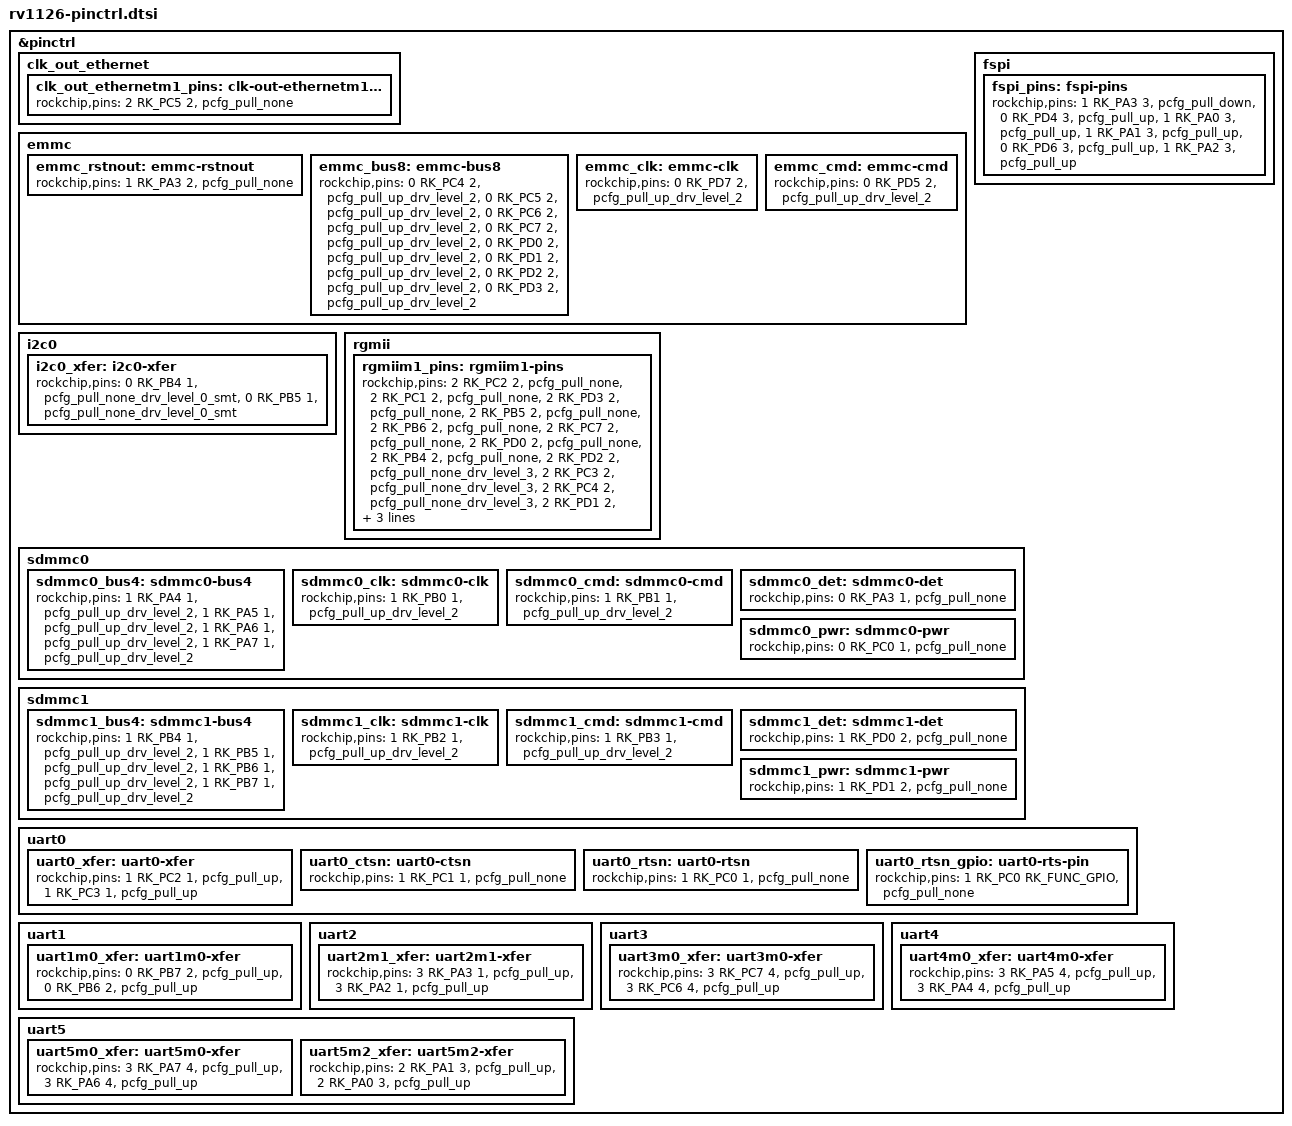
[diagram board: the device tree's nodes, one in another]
#include <dt-bindings/pinctrl/rockchip.h>
#include <arm64/rockchip/rockchip-pinconf.dtsi>
&pinctrl {
	clk_out_ethernet {
		/omit-if-no-ref/
		clk_out_ethernetm1_pins: clk-out-ethernetm1-pins {
			rockchip,pins =
				<2 RK_PC5 2 &pcfg_pull_none>;
		};
	};
	emmc {
		/omit-if-no-ref/
		emmc_rstnout: emmc-rstnout {
			rockchip,pins =
				<1 RK_PA3 2 &pcfg_pull_none>;
		};
		/omit-if-no-ref/
		emmc_bus8: emmc-bus8 {
			rockchip,pins =
				<0 RK_PC4 2 &pcfg_pull_up_drv_level_2>,
				<0 RK_PC5 2 &pcfg_pull_up_drv_level_2>,
				<0 RK_PC6 2 &pcfg_pull_up_drv_level_2>,
				<0 RK_PC7 2 &pcfg_pull_up_drv_level_2>,
				<0 RK_PD0 2 &pcfg_pull_up_drv_level_2>,
				<0 RK_PD1 2 &pcfg_pull_up_drv_level_2>,
				<0 RK_PD2 2 &pcfg_pull_up_drv_level_2>,
				<0 RK_PD3 2 &pcfg_pull_up_drv_level_2>;
		};
		/omit-if-no-ref/
		emmc_clk: emmc-clk {
			rockchip,pins =
				<0 RK_PD7 2 &pcfg_pull_up_drv_level_2>;
		};
		/omit-if-no-ref/
		emmc_cmd: emmc-cmd {
			rockchip,pins =
				<0 RK_PD5 2 &pcfg_pull_up_drv_level_2>;
		};
	};
	fspi {
		/omit-if-no-ref/
		fspi_pins: fspi-pins {
			rockchip,pins =
				<1 RK_PA3 3 &pcfg_pull_down>,
				<0 RK_PD4 3 &pcfg_pull_up>,
				<1 RK_PA0 3 &pcfg_pull_up>,
				<1 RK_PA1 3 &pcfg_pull_up>,
				<0 RK_PD6 3 &pcfg_pull_up>,
				<1 RK_PA2 3 &pcfg_pull_up>;
		};
	};
	i2c0 {
		/omit-if-no-ref/
		i2c0_xfer: i2c0-xfer {
			rockchip,pins =
				<0 RK_PB4 1 &pcfg_pull_none_drv_level_0_smt>,
				<0 RK_PB5 1 &pcfg_pull_none_drv_level_0_smt>;
		};
	};
	rgmii {
		/omit-if-no-ref/
		rgmiim1_pins: rgmiim1-pins {
			rockchip,pins =
				<2 RK_PC2 2 &pcfg_pull_none>,
				<2 RK_PC1 2 &pcfg_pull_none>,
				<2 RK_PD3 2 &pcfg_pull_none>,
				<2 RK_PB5 2 &pcfg_pull_none>,
				<2 RK_PB6 2 &pcfg_pull_none>,
				<2 RK_PC7 2 &pcfg_pull_none>,
				<2 RK_PD0 2 &pcfg_pull_none>,
				<2 RK_PB4 2 &pcfg_pull_none>,
				<2 RK_PD2 2 &pcfg_pull_none_drv_level_3>,
				<2 RK_PC3 2 &pcfg_pull_none_drv_level_3>,
				<2 RK_PC4 2 &pcfg_pull_none_drv_level_3>,
				<2 RK_PD1 2 &pcfg_pull_none_drv_level_3>,
				<2 RK_PA4 2 &pcfg_pull_none_drv_level_3>,
				<2 RK_PC6 2 &pcfg_pull_none_drv_level_3>;
		};
	};
	sdmmc0 {
		/omit-if-no-ref/
		sdmmc0_bus4: sdmmc0-bus4 {
			rockchip,pins =
				<1 RK_PA4 1 &pcfg_pull_up_drv_level_2>,
				<1 RK_PA5 1 &pcfg_pull_up_drv_level_2>,
				<1 RK_PA6 1 &pcfg_pull_up_drv_level_2>,
				<1 RK_PA7 1 &pcfg_pull_up_drv_level_2>;
		};
		/omit-if-no-ref/
		sdmmc0_clk: sdmmc0-clk {
			rockchip,pins =
				<1 RK_PB0 1 &pcfg_pull_up_drv_level_2>;
		};
		/omit-if-no-ref/
		sdmmc0_cmd: sdmmc0-cmd {
			rockchip,pins =
				<1 RK_PB1 1 &pcfg_pull_up_drv_level_2>;
		};
		/omit-if-no-ref/
		sdmmc0_det: sdmmc0-det {
			rockchip,pins =
				<0 RK_PA3 1 &pcfg_pull_none>;
		};
		/omit-if-no-ref/
		sdmmc0_pwr: sdmmc0-pwr {
			rockchip,pins =
				<0 RK_PC0 1 &pcfg_pull_none>;
		};
	};
	sdmmc1 {
		/omit-if-no-ref/
		sdmmc1_bus4: sdmmc1-bus4 {
			rockchip,pins =
				<1 RK_PB4 1 &pcfg_pull_up_drv_level_2>,
				<1 RK_PB5 1 &pcfg_pull_up_drv_level_2>,
				<1 RK_PB6 1 &pcfg_pull_up_drv_level_2>,
				<1 RK_PB7 1 &pcfg_pull_up_drv_level_2>;
		};
		/omit-if-no-ref/
		sdmmc1_clk: sdmmc1-clk {
			rockchip,pins =
				<1 RK_PB2 1 &pcfg_pull_up_drv_level_2>;
		};
		/omit-if-no-ref/
		sdmmc1_cmd: sdmmc1-cmd {
			rockchip,pins =
				<1 RK_PB3 1 &pcfg_pull_up_drv_level_2>;
		};
		/omit-if-no-ref/
		sdmmc1_det: sdmmc1-det {
			rockchip,pins =
				<1 RK_PD0 2 &pcfg_pull_none>;
		};
		/omit-if-no-ref/
		sdmmc1_pwr: sdmmc1-pwr {
			rockchip,pins =
				<1 RK_PD1 2 &pcfg_pull_none>;
		};
	};
	uart0 {
		/omit-if-no-ref/
		uart0_xfer: uart0-xfer {
			rockchip,pins =
				<1 RK_PC2 1 &pcfg_pull_up>,
				<1 RK_PC3 1 &pcfg_pull_up>;
		};
		/omit-if-no-ref/
		uart0_ctsn: uart0-ctsn {
			rockchip,pins =
				<1 RK_PC1 1 &pcfg_pull_none>;
		};
		/omit-if-no-ref/
		uart0_rtsn: uart0-rtsn {
			rockchip,pins =
				<1 RK_PC0 1 &pcfg_pull_none>;
		};
		/omit-if-no-ref/
		uart0_rtsn_gpio: uart0-rts-pin {
			rockchip,pins =
				<1 RK_PC0 RK_FUNC_GPIO &pcfg_pull_none>;
		};
	};
	uart1 {
		/omit-if-no-ref/
		uart1m0_xfer: uart1m0-xfer {
			rockchip,pins =
				<0 RK_PB7 2 &pcfg_pull_up>,
				<0 RK_PB6 2 &pcfg_pull_up>;
		};
	};
	uart2 {
		/omit-if-no-ref/
		uart2m1_xfer: uart2m1-xfer {
			rockchip,pins =
				<3 RK_PA3 1 &pcfg_pull_up>,
				<3 RK_PA2 1 &pcfg_pull_up>;
		};
	};
	uart3 {
		/omit-if-no-ref/
		uart3m0_xfer: uart3m0-xfer {
			rockchip,pins =
				<3 RK_PC7 4 &pcfg_pull_up>,
				<3 RK_PC6 4 &pcfg_pull_up>;
		};
	};
	uart4 {
		/omit-if-no-ref/
		uart4m0_xfer: uart4m0-xfer {
			rockchip,pins =
				<3 RK_PA5 4 &pcfg_pull_up>,
				<3 RK_PA4 4 &pcfg_pull_up>;
		};
	};
	uart5 {
		/omit-if-no-ref/
		uart5m0_xfer: uart5m0-xfer {
			rockchip,pins =
				<3 RK_PA7 4 &pcfg_pull_up>,
				<3 RK_PA6 4 &pcfg_pull_up>;
		};
		/omit-if-no-ref/
		uart5m2_xfer: uart5m2-xfer {
			rockchip,pins =
				<2 RK_PA1 3 &pcfg_pull_up>,
				<2 RK_PA0 3 &pcfg_pull_up>;
		};
	};
};
